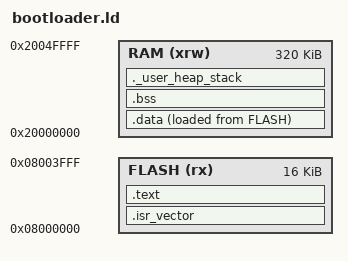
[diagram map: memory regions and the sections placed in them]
ENTRY(Reset_Handler)

MEMORY
{
  FLASH (rx)      : ORIGIN = 0x08000000, LENGTH = 16K
  RAM (xrw)       : ORIGIN = 0x20000000, LENGTH = 320K
}

SECTIONS
{
  .isr_vector :
  {
    . = ALIGN(4);
    KEEP(*(.isr_vector))
    . = ALIGN(4);
  } >FLASH

  .text :
  {
    . = ALIGN(4);
    *(.text)
    *(.text*)
    *(.glue_7)
    *(.glue_7t)
    *(.eh_frame)
    *(.init)
    *(.fini)
    *(.rodata)
    *(.rodata*)
    . = ALIGN(4);
    _etext = .;
  } >FLASH

  _sidata = LOADADDR(.data);

  .data :
  {
    . = ALIGN(4);
    _sdata = .;
    *(.data)
    *(.data*)
    . = ALIGN(4);
    _edata = .;
  } >RAM AT> FLASH

  .bss :
  {
    . = ALIGN(4);
    _sbss = .;
    __bss_start__ = _sbss;
    *(.bss)
    *(.bss*)
    *(COMMON)
    . = ALIGN(4);
    _ebss = .;
    __bss_end__ = _ebss;
  } >RAM

  ._user_heap_stack :
  {
    . = ALIGN(8);
    PROVIDE ( end = . );
    PROVIDE ( _end = . );
    . = . + 0x2000; /* 8KB Stack */
    _estack = .;
  } >RAM
}
